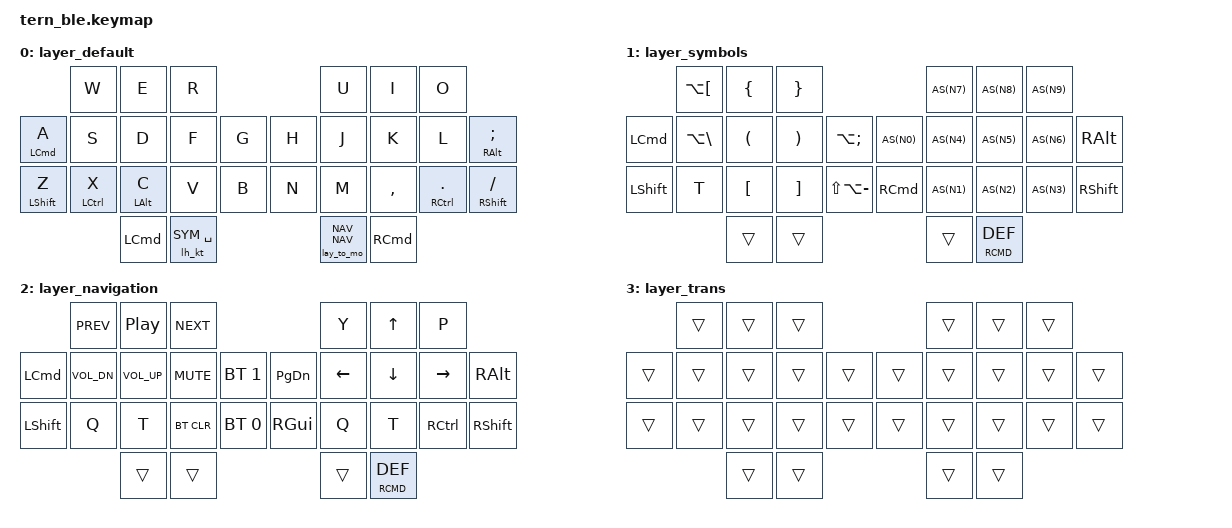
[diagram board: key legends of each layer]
/*
 * Copyright (c) 2022 Gleb Sabirzyanov
 *
 * SPDX-License-Identifier: MIT
 */

#include <behaviors.dtsi>
#include <dt-bindings/zmk/keys.h>
#include <dt-bindings/zmk/bt.h>
#include "../../../../zmk-nodefree-config/helper.h"
// https://github.com/urob/zmk-nodefree-config

#undef COMBO_TERM
#define COMBO_TERM 20
#include "combos.def"

// Layers
#define DEF 0
#define SYM 1
#define NAV 2

// tap ctrl many times for bootloader
ZMK_BEHAVIOR(ctrl_tap_bootloader, tap_dance,
    tapping-term-ms = <100>;
    bindings = <&kp LCTRL>, <&kp LCTRL>, <&kp LCTRL>, <&kp LCTRL>, <&bootloader>;
)

// tap shift twice for capsword
ZMK_BEHAVIOR(dt_capsword, tap_dance,
    tapping-term-ms = <100>;
    bindings = <&kp RSHIFT>, <&caps_word>;
)

// hit space to go to default layer
ZMK_BEHAVIOR(spc_def, macro,
    wait-ms = <0>;
    tap-ms = <0>;
    bindings =
        <&kp SPACE>,
        <&to DEF>
        ;
)

ZMK_BEHAVIOR(mt_sp, hold_tap,
    flavor = "hold-preferred";
    tapping-term-ms = <100>;
    quick-tap-ms = <100>;
    bindings = <&mo>, <&spc_def>;
)

// https://zmk.dev/docs/behaviors/hold-tap

// keycode hold/layer tap quick
ZMK_BEHAVIOR(lt_q, hold_tap,
    flavor = "hold-preferred";
    tapping-term-ms = <100>;
    quick-tap-ms = <100>;
    bindings = <&kp>, <&to>;
)

// layer hold/keycode tap quick
ZMK_BEHAVIOR(lh_kt, hold_tap,
    flavor = "hold-preferred";
    tapping-term-ms = <100>;
    quick-tap-ms = <100>;
    bindings = <&to>, <&kp>;
)

// quick layer toggle or momentary
ZMK_BEHAVIOR(lay_to_mo, hold_tap,
    flavor = "hold-preferred";
    tapping-term-ms = <100>;
    bindings = <&mo>, <&to>;
)

// Autoshift Macro
#define AS(keycode) &autoshift LS(keycode) keycode     

ZMK_BEHAVIOR(autoshift, hold_tap,
    tapping_term_ms = <135>;
    quick_tap_ms = <0>;
    flavor = "tap-preferred";
    bindings = <&kp>, <&kp>;
)

// mod tap slow for command/ctrl
ZMK_BEHAVIOR(mt_s, hold_tap,
    flavor = "balanced";
    tapping-term-ms = <100>;
    global-quick-tap;
    quick-tap-ms = <100>;
    bindings = <&kp>, <&kp>;
)

// mod tap quick for shift
ZMK_BEHAVIOR(mt_q, hold_tap,
    flavor = "hold-preferred";
    tapping-term-ms = <100>;
    quick-tap-ms = <100>;
    bindings = <&kp>, <&kp>;
)

/ {
    keymap {
        compatible = "zmk,keymap";
        
        layer_default {
            bindings = <
                                &kp W          &kp E         &kp R                           &kp U     &kp I     &kp O
                &mt_s LCMD A    &kp S          &kp D         &kp F     &kp G       &kp H     &kp J     &kp K     &kp L            &mt_s RALT SEMI
                &mt_q LSHIFT Z  &mt_s LCTRL X  &mt_s LALT C  &kp V     &kp B       &kp N     &kp M     &kp COMMA &mt_s RCTRL DOT  &mt_q RSHIFT SLASH
                                         &kp LCMD &lh_kt SYM SPACE                     &lay_to_mo NAV NAV &kp RCMD
            >;
        };

        layer_symbols {
            bindings = <
                           &kp LA(LBKT) &kp LBRC  &kp RBRC                                     AS(N7) AS(N8) AS(N9)
                &kp LCMD   &kp LA(BSLH) &kp LPAR  &kp RPAR  &kp LA(SEMI)             AS(N0)    AS(N4) AS(N5) AS(N6) &kp RALT
                &kp LSHIFT &kp T        &kp LBKT  &kp RBKT  &kp LS(LA(MINUS))        &kp RCMD  AS(N1) AS(N2) AS(N3) &kp RSHIFT
                                                       &trans &trans                    &trans &lt_q RCMD DEF 
            >;
        };

        layer_navigation {
            bindings = <
                             &kp C_PREV    &kp C_PLAY_PAUSE   &kp C_NEXT                                        &kp Y       &kp UP     &kp P 
                &kp LCMD     &kp C_VOL_DN  &kp C_VOL_UP       &kp C_MUTE  &bt BT_SEL 1          &kp PAGE_DOWN   &kp LEFT    &kp DOWN   &kp RIGHT   &kp RALT
                &kp LSHIFT   &kp Q         &kp T              &bt BT_CLR  &bt BT_SEL 0          &kp RGUI        &kp Q       &kp T      &kp RCTRL   &kp RSHIFT
                                                                      &trans &trans                 &trans &lt_q RCMD DEF
            >;
        };

        layer_trans {
            bindings = <
                           // 0       1          2                                     3          4          5
                           &trans     &trans     &trans                                &trans     &trans     &trans
                // 6       7          8          9          10              11         12         13         14         15
                &trans     &trans     &trans     &trans     &trans          &trans     &trans     &trans     &trans     &trans
                &trans     &trans     &trans     &trans     &trans          &trans     &trans     &trans     &trans     &trans
                                                     // 26  27         28     29
                                                     &trans &trans     &trans &trans
            >;
            
        };
    };
};
